# S32K148 register map
Vendor: NXP; Series: S32K; File version: 1.6
CPU: CM4 r0p1, little endian, MPU, FPU, 4 interrupt priority bits
Registers are 32-bit, read-write, reset 0x0 unless marked. A register's access mark holds for its fields unless they carry their own. Offsets are from the block's base; [hi:lo] are bit positions; {n}, {i} and the like mark numbered series; 'fields as' and 'values as' point back to an identical list.

## WDOG — Watchdog timer
Base 0x40052000; register names take the prefix WDOG_
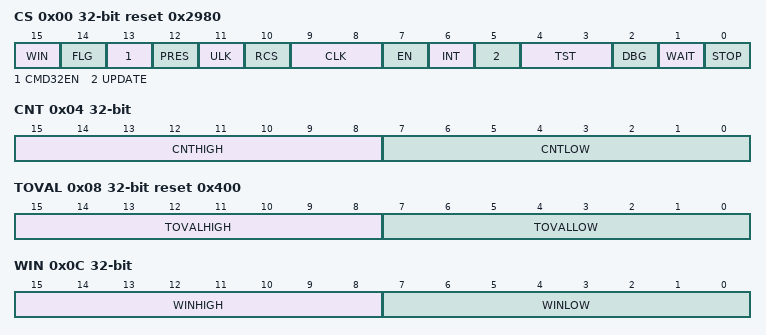
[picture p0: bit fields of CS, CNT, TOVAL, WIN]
0x00 CS reset 0x2980 — Watchdog Control and Status Register
  [15] WIN — Watchdog Window
    0=Window mode disabled; 1=Window mode enabled
  [14] FLG — Watchdog Interrupt Flag
    0=No interrupt occurred; 1=An interrupt occurred
  [13] CMD32EN — Enables or disables WDOG support for 32-bit (otherwise 16-bit or 8-bit) refresh/unlock command write words
    0=Disables support for 32-bit refresh/unlock command write words. Only 16-bit or 8-bit is supported.; 1=Enables support for 32-bit refresh/unlock command write words. 16-bit or 8-bit is NOT supported.
  [12] PRES — Watchdog prescaler
    0=256 prescaler disabled; 1=256 prescaler enabled
  [11] ULK ro — Unlock status
    0=WDOG is locked; 1=WDOG is unlocked
  [10] RCS ro — Reconfiguration Success
    0=Reconfiguring WDOG; 1=Reconfiguration is successful
  [9:8] CLK — Watchdog Clock
    0=Bus clock; 1=LPO clock; 2=INTCLK (internal clock); 3=ERCLK (external reference clock)
  [7] EN — Watchdog Enable
    0=Watchdog disabled; 1=Watchdog enabled
  [6] INT — Watchdog Interrupt
    0=Watchdog interrupts are disabled. Watchdog resets are not delayed.; 1=Watchdog interrupts are enabled. Watchdog resets are delayed by 8'd128 bus clocks from the interrupt vector fetch.
  [5] UPDATE — Allow updates
    0=Updates not allowed. After the initial configuration, the watchdog cannot be later modified without forcing a reset.; 1=Updates allowed. Software can modify the watchdog configuration registers within 8'd128 bus clocks after performing the unlock write sequence.
  [4:3] TST — Watchdog Test
    0=Watchdog test mode disabled; 1=Watchdog user mode enabled. (Watchdog test mode disabled.) After testing the watchdog, software should use this setting to indicate that the watchdog is functioning normally in user mode.; 2=Watchdog test mode enabled, only the low byte is used. CNT[CNTLOW] is compared with TOVAL[TOVALLOW].; 3=Watchdog test mode enabled, only the high byte is used. CNT[CNTHIGH] is compared with TOVAL[TOVALHIGH].
  [2] DBG — Debug Enable
    0=Watchdog disabled in chip debug mode; 1=Watchdog enabled in chip debug mode
  [1] WAIT — Wait Enable
    0=Watchdog disabled in chip wait mode; 1=Watchdog enabled in chip wait mode
  [0] STOP — Stop Enable
    0=Watchdog disabled in chip stop mode; 1=Watchdog enabled in chip stop mode
0x04 CNT — Watchdog Counter Register
  [15:8] CNTHIGH — High byte of the Watchdog Counter
  [7:0] CNTLOW — Low byte of the Watchdog Counter
0x08 TOVAL reset 0x400 — Watchdog Timeout Value Register
  [15:8] TOVALHIGH — High byte of the timeout value
  [7:0] TOVALLOW — Low byte of the timeout value
0x0C WIN — Watchdog Window Register
  [15:8] WINHIGH — High byte of Watchdog Window
  [7:0] WINLOW — Low byte of Watchdog Window

## EWM — External Watchdog Monitor
Base 0x40061000; register names take the prefix EWM_
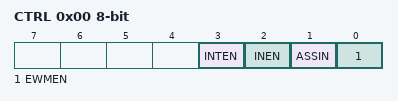
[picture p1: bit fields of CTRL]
0x00 CTRL 8-bit — Control Register
  [3] INTEN — Interrupt Enable.
  [2] INEN write-once — Input Enable.
  [1] ASSIN write-once — EWM_in's Assertion State Select.
  [0] EWMEN write-once — EWM enable.
0x01 SERV 8-bit wo — Service Register
  [7:0] SERVICE
0x02 CMPL 8-bit write-once — Compare Low Register
  [7:0] COMPAREL
0x03 CMPH 8-bit write-once reset 0xFF — Compare High Register
  [7:0] COMPAREH
0x05 CLKPRESCALER 8-bit write-once — Clock Prescaler Register
  [7:0] CLK_DIV

## TRGMUX
Base 0x40063000
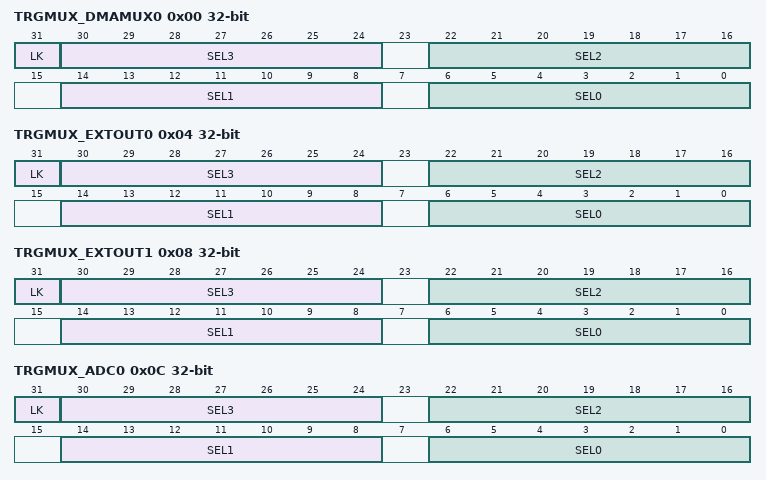
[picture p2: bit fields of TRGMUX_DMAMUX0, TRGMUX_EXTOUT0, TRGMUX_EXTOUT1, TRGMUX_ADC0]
0x00 TRGMUX_DMAMUX0
  [31] LK — TRGMUX register lock.
    0=Register can be written; 1=Register cannot be written until the next system Reset
  [8n+6:8n] SEL{n} (n=0..3) — Trigger MUX Input {n} Source Select
0x04 TRGMUX_EXTOUT0
  fields as TRGMUX_DMAMUX0
0x08 TRGMUX_EXTOUT1
  fields as TRGMUX_DMAMUX0
0x0C TRGMUX_ADC0
  fields as TRGMUX_DMAMUX0
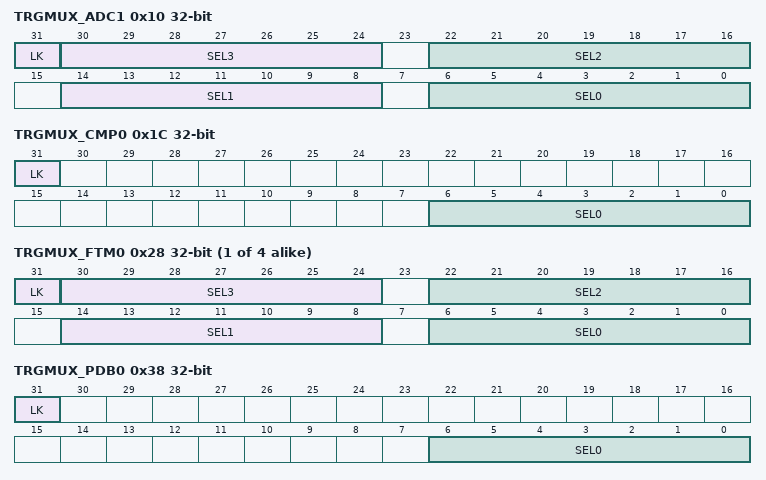
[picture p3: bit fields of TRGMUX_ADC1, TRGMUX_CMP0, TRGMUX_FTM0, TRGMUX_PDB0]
0x10 TRGMUX_ADC1
  fields as TRGMUX_DMAMUX0
0x1C TRGMUX_CMP0
  [31] LK — TRGMUX register lock.
    values as TRGMUX_DMAMUX0.LK
  [6:0] SEL0 — Trigger MUX Input 0 Source Select
{0x28+4i} TRGMUX_FTM{i} (i=0..3)
  fields as TRGMUX_DMAMUX0
0x38 TRGMUX_PDB0
  fields as TRGMUX_CMP0
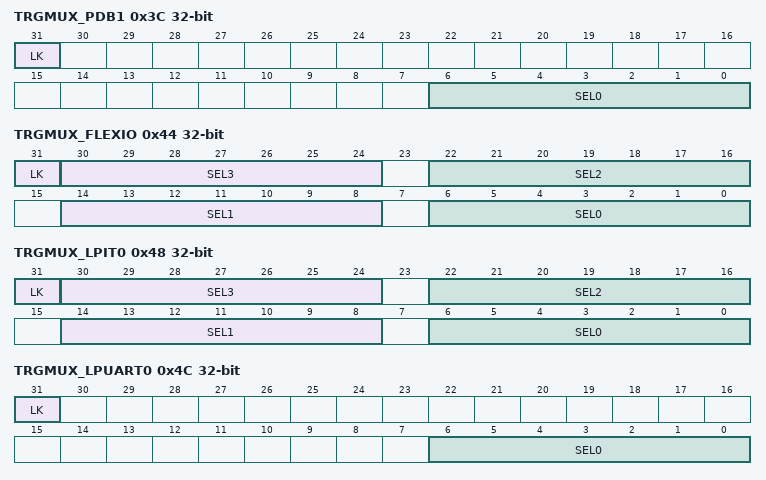
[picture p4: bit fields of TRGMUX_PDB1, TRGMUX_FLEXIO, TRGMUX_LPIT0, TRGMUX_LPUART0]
0x3C TRGMUX_PDB1
  fields as TRGMUX_CMP0
0x44 TRGMUX_FLEXIO
  fields as TRGMUX_DMAMUX0
0x48 TRGMUX_LPIT0
  fields as TRGMUX_DMAMUX0
0x4C TRGMUX_LPUART0
  fields as TRGMUX_CMP0
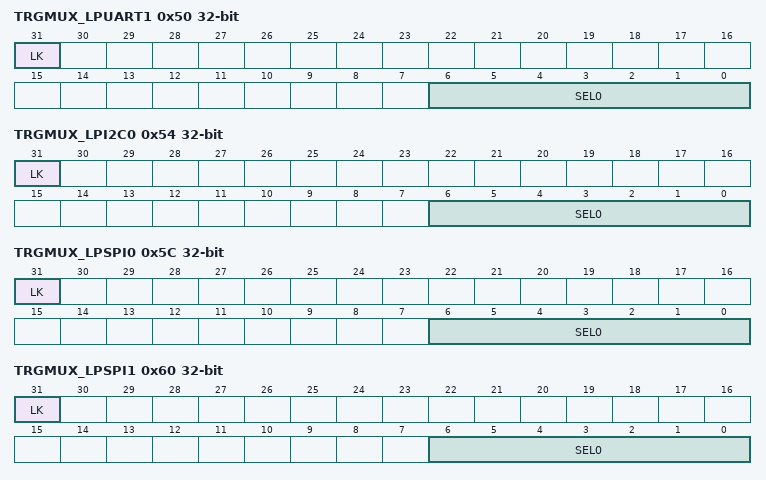
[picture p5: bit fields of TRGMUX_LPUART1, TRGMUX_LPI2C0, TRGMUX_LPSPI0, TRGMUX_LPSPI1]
0x50 TRGMUX_LPUART1
  fields as TRGMUX_CMP0
0x54 TRGMUX_LPI2C0
  fields as TRGMUX_CMP0
0x5C TRGMUX_LPSPI0
  fields as TRGMUX_CMP0
0x60 TRGMUX_LPSPI1
  fields as TRGMUX_CMP0
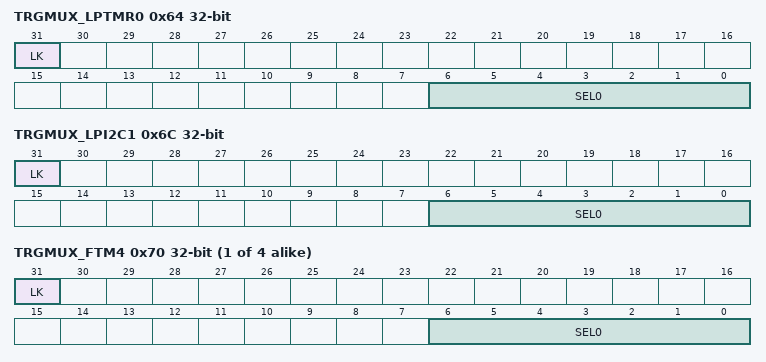
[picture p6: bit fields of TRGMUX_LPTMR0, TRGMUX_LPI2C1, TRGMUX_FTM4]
0x64 TRGMUX_LPTMR0
  fields as TRGMUX_CMP0
0x6C TRGMUX_LPI2C1
  fields as TRGMUX_CMP0
{0x60+4i} TRGMUX_FTM{i} (i=4..7)
  fields as TRGMUX_CMP0
